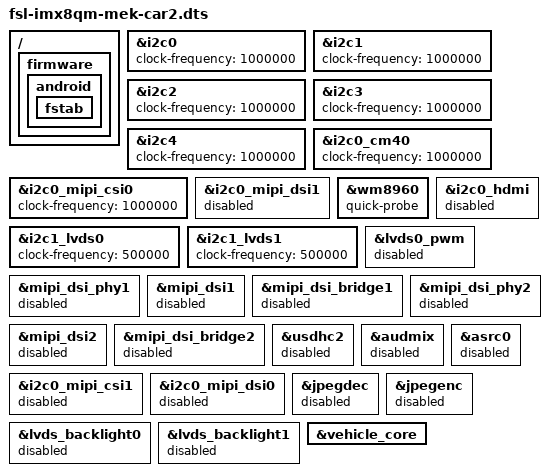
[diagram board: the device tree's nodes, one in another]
/*
 * Copyright 2018 NXP
 *
 * This program is free software; you can redistribute it and/or
 * modify it under the terms of the GNU General Public License
 * as published by the Free Software Foundation; either version 2
 * of the License, or (at your option) any later version.
 *
 * This program is distributed in the hope that it will be useful,
 * but WITHOUT ANY WARRANTY; without even the implied warranty of
 * MERCHANTABILITY or FITNESS FOR A PARTICULAR PURPOSE.  See the
 * GNU General Public License for more details.
 */

#include "fsl-imx8qm-mek-car-common.dtsi"

&i2c0 {
	clock-frequency = <1000000>;
};

&i2c1 {
	clock-frequency = <1000000>;
};

&i2c2 {
	clock-frequency = <1000000>;
};

&i2c3 {
	clock-frequency = <1000000>;
};

&i2c4 {
	clock-frequency = <1000000>;
};

&i2c0_cm40 {
	clock-frequency = <1000000>;
};

&i2c0_mipi_csi0 {
	clock-frequency = <1000000>;
};

&i2c0_mipi_dsi1 {
	status = "disabled";
};

&wm8960 {
	quick-probe;
};

&i2c0_hdmi {
	status = "disabled";
};

&i2c1_lvds0 {
	clock-frequency = <500000>;
};

&i2c1_lvds1 {
	clock-frequency = <500000>;
};

&lvds0_pwm {
	status = "disabled";
};

&mipi_dsi_phy1 {
	status = "disabled";
};

&mipi_dsi1 {
	status = "disabled";
};

&mipi_dsi_bridge1 {
	status = "disabled";
};

&mipi_dsi_phy2 {
   status = "disabled";
};

&mipi_dsi2 {
   status = "disabled";
};

&mipi_dsi_bridge2 {
   status = "disabled";
};

&usdhc2 {
	status = "disabled";
};

&audmix {
	status = "disabled";
};

&asrc0 {
	status = "disabled";
};

&i2c0_mipi_csi1 {
	status = "disabled";
};

&i2c0_mipi_dsi0 {
	status = "disabled";
};

&jpegdec {
	status = "disabled";
};

&jpegenc {
	status = "disabled";
};

&lvds_backlight0 {
	status = "disabled";
};

&lvds_backlight1 {
	status = "disabled";
};

&vehicle_core {
	status = "okay";
};

/ {
	firmware {
		android {
			fstab {
				/delete-node/ system;
			};
		};
	};
};
